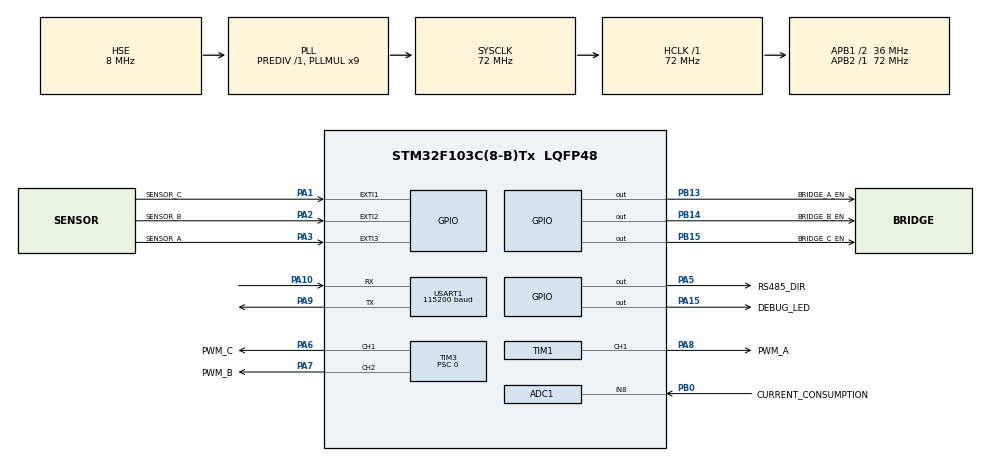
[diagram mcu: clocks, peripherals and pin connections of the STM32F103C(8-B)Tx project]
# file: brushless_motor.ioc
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ADC1.AWD1HighThreshold=3686
ADC1.AWD1ITMode=ENABLE
ADC1.AWD1LowThreshold=409
ADC1.Channel-0\#ChannelRegularConversion=ADC_CHANNEL_8
ADC1.ContinuousConvMode=ENABLE
ADC1.DataAlign=ADC_DATAALIGN_RIGHT
ADC1.DiscontinuousConvMode=DISABLE
ADC1.EnableAnalogWatchDog=true
ADC1.EnableRegularConversion=ENABLE
ADC1.ExternalTrigConv=ADC_SOFTWARE_START
ADC1.InjNumberOfConversion=0
ADC1.NbrOfConversion=1
ADC1.NbrOfConversionFlag=1
ADC1.Rank-0\#ChannelRegularConversion=1
ADC1.SamplingTime-0\#ChannelRegularConversion=ADC_SAMPLETIME_1CYCLE_5
ADC1.ScanConvMode=ADC_SCAN_DISABLE
ADC1.WatchdogChannel=ADC_CHANNEL_8
ADC1.WatchdogMode=ADC_ANALOGWATCHDOG_SINGLE_REG
ADC1.master=1
Dma.ADC1.1.Direction=DMA_PERIPH_TO_MEMORY
Dma.ADC1.1.Instance=DMA1_Channel1
Dma.ADC1.1.MemDataAlignment=DMA_MDATAALIGN_HALFWORD
Dma.ADC1.1.MemInc=DMA_MINC_ENABLE
Dma.ADC1.1.Mode=DMA_CIRCULAR
Dma.ADC1.1.PeriphDataAlignment=DMA_PDATAALIGN_HALFWORD
Dma.ADC1.1.PeriphInc=DMA_PINC_DISABLE
Dma.ADC1.1.Priority=DMA_PRIORITY_LOW
Dma.Request0=USART1_TX
Dma.Request1=ADC1
Dma.USART1_TX.0.Direction=DMA_MEMORY_TO_PERIPH
Dma.USART1_TX.0.Instance=DMA1_Channel4
Dma.USART1_TX.0.MemDataAlignment=DMA_MDATAALIGN_BYTE
Dma.USART1_TX.0.MemInc=DMA_MINC_ENABLE
Dma.USART1_TX.0.Mode=DMA_NORMAL
Dma.USART1_TX.0.PeriphDataAlignment=DMA_PDATAALIGN_BYTE
Dma.USART1_TX.0.PeriphInc=DMA_PINC_DISABLE
Dma.USART1_TX.0.Priority=DMA_PRIORITY_LOW
Mcu.Family=STM32F1
Mcu.Name=STM32F103C(8-B)Tx
Mcu.Package=LQFP48
NVIC.ADC1_2_IRQn=true\:0\:0\:true\:false\:true\:true\:true
NVIC.DMA1_Channel1_IRQn=true\:2\:0\:true\:false\:true\:false\:true
NVIC.DMA1_Channel4_IRQn=true\:2\:0\:true\:false\:true\:false\:true
NVIC.EXTI1_IRQn=true\:0\:0\:false\:false\:true\:true\:true
NVIC.EXTI2_IRQn=true\:0\:0\:false\:false\:true\:true\:true
NVIC.EXTI3_IRQn=true\:0\:0\:false\:false\:true\:true\:true
NVIC.PriorityGroup=NVIC_PRIORITYGROUP_4
NVIC.TIM1_UP_IRQn=true\:1\:0\:true\:false\:true\:true\:true
NVIC.TIM3_IRQn=true\:1\:0\:true\:false\:true\:true\:true
NVIC.USART1_IRQn=true\:1\:0\:true\:false\:true\:true\:true
PA1.GPIO_Label=SENSOR_C
PA1.GPIO_ModeDefaultEXTI=GPIO_MODE_IT_RISING_FALLING
PA1.GPIO_PuPd=GPIO_PULLUP
PA1.Signal=GPXTI1
PA10.GPIO_PuPd=GPIO_PULLUP
PA10.Mode=Asynchronous
PA10.Signal=USART1_RX
PA13.Mode=Trace_Asynchronous_SW
PA13.Signal=SYS_JTMS-SWDIO
PA14.Mode=Trace_Asynchronous_SW
PA14.Signal=SYS_JTCK-SWCLK
PA15.GPIO_Label=DEBUG_LED
PA15.GPIO_Speed=GPIO_SPEED_FREQ_MEDIUM
PA15.PinState=GPIO_PIN_RESET
PA15.Signal=GPIO_Output
PA2.GPIO_Label=SENSOR_B
PA2.GPIO_ModeDefaultEXTI=GPIO_MODE_IT_RISING_FALLING
PA2.GPIO_PuPd=GPIO_PULLUP
PA2.Signal=GPXTI2
PA3.GPIO_Label=SENSOR_A
PA3.GPIO_ModeDefaultEXTI=GPIO_MODE_IT_RISING_FALLING
PA3.GPIO_PuPd=GPIO_PULLUP
PA3.Signal=GPXTI3
PA5.GPIO_Label=RS485_DIR
PA5.GPIO_Speed=GPIO_SPEED_FREQ_HIGH
PA5.Signal=GPIO_Output
PA6.GPIO_Label=PWM_C
PA6.GPIO_Speed=GPIO_SPEED_FREQ_HIGH
PA6.Signal=S_TIM3_CH1
PA7.GPIO_Label=PWM_B
PA7.GPIO_Speed=GPIO_SPEED_FREQ_HIGH
PA7.Signal=S_TIM3_CH2
PA8.GPIO_Label=PWM_A
PA8.GPIO_Speed=GPIO_SPEED_FREQ_HIGH
PA8.Signal=S_TIM1_CH1
PA9.Mode=Asynchronous
PA9.Signal=USART1_TX
PB0.GPIO_Label=CURRENT_CONSUMPTION
PB0.Signal=ADCx_IN8
PB13.GPIO_Label=BRIDGE_A_EN
PB13.GPIO_Speed=GPIO_SPEED_FREQ_HIGH
PB13.Signal=GPIO_Output
PB14.GPIO_Label=BRIDGE_B_EN
PB14.GPIO_Speed=GPIO_SPEED_FREQ_HIGH
PB14.Signal=GPIO_Output
PB15.GPIO_Label=BRIDGE_C_EN
PB15.GPIO_Speed=GPIO_SPEED_FREQ_HIGH
PB15.Signal=GPIO_Output
PB3.Mode=Trace_Asynchronous_SW
PB3.Signal=SYS_JTDO-TRACESWO
PD0-OSC_IN.Mode=HSE-External-Oscillator
PD0-OSC_IN.Signal=RCC_OSC_IN
PD1-OSC_OUT.Mode=HSE-External-Oscillator
PD1-OSC_OUT.Signal=RCC_OSC_OUT
ProjectManager.HeapSize=0x200
ProjectManager.StackSize=0x400
ProjectManager.TargetToolchain=MDK-ARM V5
RCC.ADCPresc=RCC_ADCPCLK2_DIV6
RCC.AHBFreq_Value=72000000
RCC.APB1CLKDivider=RCC_HCLK_DIV2
RCC.APB1Freq_Value=36000000
RCC.APB1TimFreq_Value=72000000
RCC.APB2Freq_Value=72000000
RCC.APB2TimFreq_Value=72000000
RCC.HCLKFreq_Value=72000000
RCC.PLLMUL=RCC_PLL_MUL9
RCC.PLLSourceVirtual=RCC_PLLSOURCE_HSE
RCC.SYSCLKFreq_VALUE=72000000
RCC.SYSCLKSource=RCC_SYSCLKSOURCE_PLLCLK
RCC.USBFreq_Value=72000000
SH.ADCx_IN8.0=ADC1_IN8,IN8
SH.S_TIM1_CH1.0=TIM1_CH1,PWM Generation1 CH1
SH.S_TIM3_CH1.0=TIM3_CH1,PWM Generation1 CH1
SH.S_TIM3_CH2.0=TIM3_CH2,PWM Generation2 CH2
TIM1.Channel-PWM\ Generation1\ CH1=TIM_CHANNEL_1
TIM1.CounterMode=TIM_COUNTERMODE_CENTERALIGNED1
TIM1.OCMode_PWM-PWM\ Generation1\ CH1=TIM_OCMODE_PWM2
TIM1.Period=1499
TIM1.Prescaler=0
TIM1.TIM_MasterOutputTrigger=TIM_TRGO_UPDATE
TIM1.TIM_MasterSlaveMode=TIM_MASTERSLAVEMODE_ENABLE
TIM3.Channel-PWM\ Generation1\ CH1=TIM_CHANNEL_1
TIM3.Channel-PWM\ Generation2\ CH2=TIM_CHANNEL_2
TIM3.CounterMode=TIM_COUNTERMODE_CENTERALIGNED1
TIM3.OCMode_PWM-PWM\ Generation1\ CH1=TIM_OCMODE_PWM2
TIM3.OCMode_PWM-PWM\ Generation2\ CH2=TIM_OCMODE_PWM2
TIM3.Period=1499
TIM3.Prescaler=0
USART1.BaudRate=115200
USART1.VirtualMode=VM_ASYNC
VP_TIM1_VS_ClockSourceINT.Mode=Internal
VP_TIM3_VS_ClockSourceINT.Mode=Internal
VP_TIM3_VS_ClockSourceITR.Mode=TriggerSource_ITR0
VP_TIM3_VS_ControllerModeTrigger.Mode=Trigger Mode
board=brushless_motor

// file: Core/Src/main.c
/* USER CODE BEGIN Header */
/**
  ******************************************************************************
  * @file           : main.c
  * @brief          : Main program body
  ******************************************************************************
  * @attention
  *
  * <h2><center>&copy; Copyright (c) 2019 STMicroelectronics.
  * All rights reserved.</center></h2>
  *
  * This software component is licensed by ST under BSD 3-Clause license,
  * the "License"; You may not use this file except in compliance with the
  * License. You may obtain a copy of the License at:
  *                        opensource.org/licenses/BSD-3-Clause
  *
  ******************************************************************************
  */
/* USER CODE END Header */

#include "main.h"
#include "adc.h"
#include "dma.h"
#include "tim.h"
#include "usart.h"
#include "gpio.h"

/* USER CODE BEGIN Includes */
#include "brushless_motor.h"
#include "flash_config.h"
/* USER CODE END Includes */

void SystemClock_Config(void);

int main(void)
{

  /* MCU Configuration--------------------------------------------------------*/

  /* Reset of all peripherals, Initializes the Flash interface and the Systick. */
  HAL_Init();

  /* USER CODE BEGIN Init */
	shift_interrupt_vectors(APPLICATION_ADDR);
  /* USER CODE END Init */

  /* Configure the system clock */
  SystemClock_Config();

  /* Initialize all configured peripherals */
  MX_GPIO_Init();
  MX_DMA_Init();
  MX_ADC1_Init();
  MX_TIM1_Init();
  MX_TIM3_Init();
  MX_USART1_UART_Init();
  /* USER CODE BEGIN 2 */

	HAL_TIM_Base_Start_IT(&htim1);
  HAL_TIM_PWM_Start(&htim1, TIM_CHANNEL_1);  // phase A
	HAL_TIM_PWM_Start(&htim3, TIM_CHANNEL_1);  // phase C
  HAL_TIM_PWM_Start(&htim3, TIM_CHANNEL_2);  // phase B

	HAL_ADC_Start_DMA(&hadc1, (uint32_t*)adc_buf, ADC_BUF_SIZE);

  HAL_GPIO_WritePin(RS485_DIR_GPIO_Port, RS485_DIR_Pin, GPIO_PIN_RESET);

	FLASH_ReadSettings(&BLDC);
  init(&BLDC);
  /* USER CODE END 2 */

  /* Infinite loop */
  while (1)
  {

  }
}

void SystemClock_Config(void)
{
  RCC_OscInitTypeDef RCC_OscInitStruct = {0};
  RCC_ClkInitTypeDef RCC_ClkInitStruct = {0};
  RCC_PeriphCLKInitTypeDef PeriphClkInit = {0};

  /** Initializes the CPU, AHB and APB busses clocks
  */
  RCC_OscInitStruct.OscillatorType = RCC_OSCILLATORTYPE_HSE;
  RCC_OscInitStruct.HSEState = RCC_HSE_ON;
  RCC_OscInitStruct.HSEPredivValue = RCC_HSE_PREDIV_DIV1;
  RCC_OscInitStruct.HSIState = RCC_HSI_ON;
  RCC_OscInitStruct.PLL.PLLState = RCC_PLL_ON;
  RCC_OscInitStruct.PLL.PLLSource = RCC_PLLSOURCE_HSE;
  RCC_OscInitStruct.PLL.PLLMUL = RCC_PLL_MUL9;
  if (HAL_RCC_OscConfig(&RCC_OscInitStruct) != HAL_OK)
  {
    Error_Handler();
  }
  /** Initializes the CPU, AHB and APB busses clocks
  */
  RCC_ClkInitStruct.ClockType = RCC_CLOCKTYPE_HCLK|RCC_CLOCKTYPE_SYSCLK
                              |RCC_CLOCKTYPE_PCLK1|RCC_CLOCKTYPE_PCLK2;
  RCC_ClkInitStruct.SYSCLKSource = RCC_SYSCLKSOURCE_PLLCLK;
  RCC_ClkInitStruct.AHBCLKDivider = RCC_SYSCLK_DIV1;
  RCC_ClkInitStruct.APB1CLKDivider = RCC_HCLK_DIV2;
  RCC_ClkInitStruct.APB2CLKDivider = RCC_HCLK_DIV1;

  if (HAL_RCC_ClockConfig(&RCC_ClkInitStruct, FLASH_LATENCY_2) != HAL_OK)
  {
    Error_Handler();
  }
  PeriphClkInit.PeriphClockSelection = RCC_PERIPHCLK_ADC;
  PeriphClkInit.AdcClockSelection = RCC_ADCPCLK2_DIV6;
  if (HAL_RCCEx_PeriphCLKConfig(&PeriphClkInit) != HAL_OK)
  {
    Error_Handler();
  }
}

void Error_Handler(void)
{
}

/************************ (C) COPYRIGHT STMicroelectronics *****END OF FILE****/
